AUTOSAR XML (schema 4-2-2)
package /ComponentTypes
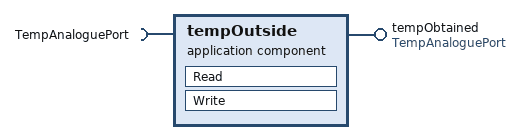
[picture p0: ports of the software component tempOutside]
  application sw component type tempOutside
    provide port tempObtained: provided-com-specs=[{data-element=tempOut, init-value=0}, {data-element=tempIn, init-value=0}], provided-interface=TempAnaloguePort
    require port TempAnaloguePort: required-com-specs=[{data-element=tempOut, init-value=0}, {data-element=tempIn, init-value=0}], required-interface=TempAnaloguePort
    behavior tempOutside_InternalBehavior: data-type-mapping=tempMapSet
      data received event DRT_Read_TempAnaloguePort_tempIn: start-on-event=Read, data=TempAnaloguePort.tempIn
      data received event DRT_Write_TempAnaloguePort_tempOut: start-on-event=Write, data=TempAnaloguePort.tempOut
      runnable Read
        data-receive-point-by-arguments:
          access REC_TempAnaloguePort_tempIn: accessed-variable=TempAnaloguePort.tempIn
      runnable Write
        data-receive-point-by-arguments:
          access REC_TempAnaloguePort_tempIn: accessed-variable=TempAnaloguePort.tempIn
        data-send-points:
          access SEND_tempObtained_tempOut: accessed-variable=tempObtained.tempOut
          access SEND_tempObtained_tempIn: accessed-variable=tempObtained.tempIn
  swc implementation tempOutside_Implementation: behavior=tempOutside_InternalBehavior
